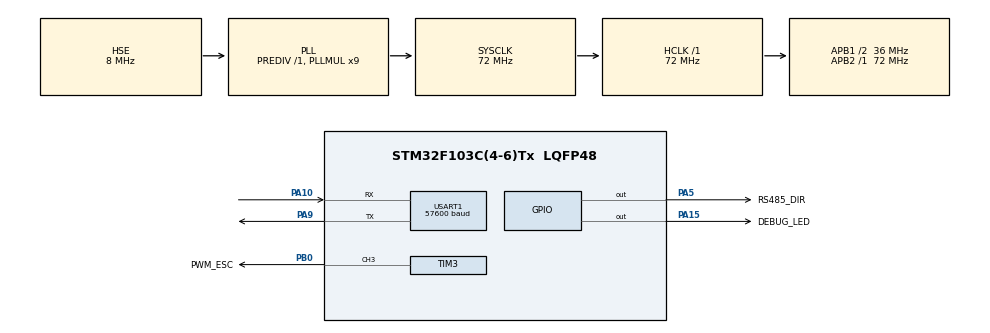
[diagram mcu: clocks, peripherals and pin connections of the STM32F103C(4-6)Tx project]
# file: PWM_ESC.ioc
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Dma.Request0=USART1_TX
Dma.Request1=USART1_RX
Dma.USART1_RX.1.Direction=DMA_PERIPH_TO_MEMORY
Dma.USART1_RX.1.Instance=DMA1_Channel5
Dma.USART1_RX.1.MemDataAlignment=DMA_MDATAALIGN_BYTE
Dma.USART1_RX.1.MemInc=DMA_MINC_ENABLE
Dma.USART1_RX.1.Mode=DMA_NORMAL
Dma.USART1_RX.1.PeriphDataAlignment=DMA_PDATAALIGN_BYTE
Dma.USART1_RX.1.PeriphInc=DMA_PINC_DISABLE
Dma.USART1_RX.1.Priority=DMA_PRIORITY_LOW
Dma.USART1_TX.0.Direction=DMA_MEMORY_TO_PERIPH
Dma.USART1_TX.0.Instance=DMA1_Channel4
Dma.USART1_TX.0.MemDataAlignment=DMA_MDATAALIGN_BYTE
Dma.USART1_TX.0.MemInc=DMA_MINC_ENABLE
Dma.USART1_TX.0.Mode=DMA_NORMAL
Dma.USART1_TX.0.PeriphDataAlignment=DMA_PDATAALIGN_BYTE
Dma.USART1_TX.0.PeriphInc=DMA_PINC_DISABLE
Dma.USART1_TX.0.Priority=DMA_PRIORITY_LOW
Mcu.Family=STM32F1
Mcu.Name=STM32F103C(4-6)Tx
Mcu.Package=LQFP48
NVIC.DMA1_Channel4_IRQn=true\:0\:0\:false\:false\:true\:false\:true
NVIC.DMA1_Channel5_IRQn=true\:0\:0\:false\:false\:true\:false\:true
NVIC.FLASH_IRQn=true\:0\:0\:false\:false\:true\:true\:true
NVIC.PriorityGroup=NVIC_PRIORITYGROUP_4
NVIC.RCC_IRQn=true\:0\:0\:false\:false\:true\:true\:false
NVIC.USART1_IRQn=true\:0\:0\:false\:false\:true\:true\:true
PA10.GPIO_PuPd=GPIO_PULLUP
PA10.Mode=Asynchronous
PA10.Signal=USART1_RX
PA13.Mode=Serial_Wire
PA13.Signal=SYS_JTMS-SWDIO
PA14.Mode=Serial_Wire
PA14.Signal=SYS_JTCK-SWCLK
PA15.GPIO_Label=DEBUG_LED
PA15.Signal=GPIO_Output
PA5.GPIO_Label=RS485_DIR
PA5.GPIO_Speed=GPIO_SPEED_FREQ_HIGH
PA5.Signal=GPIO_Output
PA9.Mode=Asynchronous
PA9.Signal=USART1_TX
PB0.GPIO_Label=PWM_ESC
PB0.Signal=S_TIM3_CH3
PD0-OSC_IN.Mode=HSE-External-Oscillator
PD0-OSC_IN.Signal=RCC_OSC_IN
PD1-OSC_OUT.Mode=HSE-External-Oscillator
PD1-OSC_OUT.Signal=RCC_OSC_OUT
ProjectManager.HeapSize=0x400
ProjectManager.StackSize=0x400
ProjectManager.TargetToolchain=TrueSTUDIO
RCC.AHBFreq_Value=72000000
RCC.APB1CLKDivider=RCC_HCLK_DIV2
RCC.APB1Freq_Value=36000000
RCC.APB1TimFreq_Value=72000000
RCC.APB2Freq_Value=72000000
RCC.APB2TimFreq_Value=72000000
RCC.HCLKFreq_Value=72000000
RCC.PLLMUL=RCC_PLL_MUL9
RCC.PLLSourceVirtual=RCC_PLLSOURCE_HSE
RCC.SYSCLKFreq_VALUE=72000000
RCC.SYSCLKSource=RCC_SYSCLKSOURCE_PLLCLK
RCC.USBFreq_Value=72000000
SH.S_TIM3_CH3.0=TIM3_CH3,PWM Generation3 CH3
TIM3.Channel-PWM\ Generation3\ CH3=TIM_CHANNEL_3
TIM3.Period=19999
TIM3.Prescaler=71
USART1.BaudRate=57600
USART1.VirtualMode=VM_ASYNC
board=custom

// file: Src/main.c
/* USER CODE BEGIN Header */
/**
  ******************************************************************************
  * @file           : main.c
  * @brief          : Main program body
  ******************************************************************************
  * @attention
  *
  * <h2><center>&copy; Copyright (c) 2020 STMicroelectronics.
  * All rights reserved.</center></h2>
  *
  * This software component is licensed by ST under BSD 3-Clause license,
  * the "License"; You may not use this file except in compliance with the
  * License. You may obtain a copy of the License at:
  *                        opensource.org/licenses/BSD-3-Clause
  *
  ******************************************************************************
  */
/* USER CODE END Header */

#include "main.h"

TIM_HandleTypeDef htim3;

UART_HandleTypeDef huart1;
DMA_HandleTypeDef hdma_usart1_tx;
DMA_HandleTypeDef hdma_usart1_rx;

/* USER CODE BEGIN PV */

extern esc_settings esc_struct;
uint8_t rx_flag = 0;
uint8_t rx_array[RECEIVE_BUFFER_SIZE] = {0};

/* USER CODE END PV */

void SystemClock_Config(void);
static void MX_GPIO_Init(void);
static void MX_DMA_Init(void);
static void MX_TIM3_Init(void);
static void MX_USART1_UART_Init(void);

int main(void)
{

  /* MCU Configuration--------------------------------------------------------*/

  /* Reset of all peripherals, Initializes the Flash interface and the Systick. */

	HAL_Init();

  /* Configure the system clock */
  SystemClock_Config();

  /* Initialize all configured peripherals */
  MX_GPIO_Init();
  MX_DMA_Init();
  MX_TIM3_Init();
  MX_USART1_UART_Init();

  /* Infinite loop */
  /* USER CODE BEGIN WHILE */

  FLASH_ReadSettings(&esc_struct);

  HAL_GPIO_WritePin(RS485_DIR_GPIO_Port, RS485_DIR_Pin, RESET);
  HAL_GPIO_WritePin(DEBUG_LED_GPIO_Port, DEBUG_LED_Pin, RESET);

  HAL_TIM_PWM_Start(&htim3, TIM_CHANNEL_3);
  esc_struct.PWM_duty = 0;
  update_esc_settings(&esc_struct);
  HAL_Delay(3000);

  HAL_UART_Receive_IT(&huart1, rx_array, 1);

  while (1)
  {
    /* USER CODE END WHILE */

  }
}

void SystemClock_Config(void)
{
  RCC_OscInitTypeDef RCC_OscInitStruct = {0};
  RCC_ClkInitTypeDef RCC_ClkInitStruct = {0};

  /** Initializes the CPU, AHB and APB busses clocks
  */
  RCC_OscInitStruct.OscillatorType = RCC_OSCILLATORTYPE_HSE;
  RCC_OscInitStruct.HSEState = RCC_HSE_ON;
  RCC_OscInitStruct.HSEPredivValue = RCC_HSE_PREDIV_DIV1;
  RCC_OscInitStruct.HSIState = RCC_HSI_ON;
  RCC_OscInitStruct.PLL.PLLState = RCC_PLL_ON;
  RCC_OscInitStruct.PLL.PLLSource = RCC_PLLSOURCE_HSE;
  RCC_OscInitStruct.PLL.PLLMUL = RCC_PLL_MUL9;
  if (HAL_RCC_OscConfig(&RCC_OscInitStruct) != HAL_OK)
  {
    Error_Handler();
  }
  /** Initializes the CPU, AHB and APB busses clocks
  */
  RCC_ClkInitStruct.ClockType = RCC_CLOCKTYPE_HCLK|RCC_CLOCKTYPE_SYSCLK
                              |RCC_CLOCKTYPE_PCLK1|RCC_CLOCKTYPE_PCLK2;
  RCC_ClkInitStruct.SYSCLKSource = RCC_SYSCLKSOURCE_PLLCLK;
  RCC_ClkInitStruct.AHBCLKDivider = RCC_SYSCLK_DIV1;
  RCC_ClkInitStruct.APB1CLKDivider = RCC_HCLK_DIV2;
  RCC_ClkInitStruct.APB2CLKDivider = RCC_HCLK_DIV1;

  if (HAL_RCC_ClockConfig(&RCC_ClkInitStruct, FLASH_LATENCY_2) != HAL_OK)
  {
    Error_Handler();
  }
}

static void MX_TIM3_Init(void)
{

  TIM_MasterConfigTypeDef sMasterConfig = {0};
  TIM_OC_InitTypeDef sConfigOC = {0};

  htim3.Instance = TIM3;
  htim3.Init.Prescaler = 71;
  htim3.Init.CounterMode = TIM_COUNTERMODE_UP;
  htim3.Init.Period = 19999;
  htim3.Init.ClockDivision = TIM_CLOCKDIVISION_DIV1;
  htim3.Init.AutoReloadPreload = TIM_AUTORELOAD_PRELOAD_DISABLE;
  if (HAL_TIM_PWM_Init(&htim3) != HAL_OK)
  {
    Error_Handler();
  }
  sMasterConfig.MasterOutputTrigger = TIM_TRGO_RESET;
  sMasterConfig.MasterSlaveMode = TIM_MASTERSLAVEMODE_DISABLE;
  if (HAL_TIMEx_MasterConfigSynchronization(&htim3, &sMasterConfig) != HAL_OK)
  {
    Error_Handler();
  }
  sConfigOC.OCMode = TIM_OCMODE_PWM1;
  sConfigOC.Pulse = 0;
  sConfigOC.OCPolarity = TIM_OCPOLARITY_HIGH;
  sConfigOC.OCFastMode = TIM_OCFAST_DISABLE;
  if (HAL_TIM_PWM_ConfigChannel(&htim3, &sConfigOC, TIM_CHANNEL_3) != HAL_OK)
  {
    Error_Handler();
  }
  HAL_TIM_MspPostInit(&htim3);

}

static void MX_USART1_UART_Init(void)
{

  huart1.Instance = USART1;
  huart1.Init.BaudRate = 57600;
  huart1.Init.WordLength = UART_WORDLENGTH_8B;
  huart1.Init.StopBits = UART_STOPBITS_1;
  huart1.Init.Parity = UART_PARITY_NONE;
  huart1.Init.Mode = UART_MODE_TX_RX;
  huart1.Init.HwFlowCtl = UART_HWCONTROL_NONE;
  huart1.Init.OverSampling = UART_OVERSAMPLING_16;
  if (HAL_UART_Init(&huart1) != HAL_OK)
  {
    Error_Handler();
  }

}

static void MX_DMA_Init(void)
{

  /* DMA controller clock enable */
  __HAL_RCC_DMA1_CLK_ENABLE();

  /* DMA interrupt init */
  /* DMA1_Channel4_IRQn interrupt configuration */
  HAL_NVIC_SetPriority(DMA1_Channel4_IRQn, 0, 0);
  HAL_NVIC_EnableIRQ(DMA1_Channel4_IRQn);
  /* DMA1_Channel5_IRQn interrupt configuration */
  HAL_NVIC_SetPriority(DMA1_Channel5_IRQn, 0, 0);
  HAL_NVIC_EnableIRQ(DMA1_Channel5_IRQn);

}

static void MX_GPIO_Init(void)
{
  GPIO_InitTypeDef GPIO_InitStruct = {0};

  /* GPIO Ports Clock Enable */
  __HAL_RCC_GPIOD_CLK_ENABLE();
  __HAL_RCC_GPIOA_CLK_ENABLE();
  __HAL_RCC_GPIOB_CLK_ENABLE();

  /*Configure GPIO pin Output Level */
  HAL_GPIO_WritePin(GPIOA, RS485_DIR_Pin|DEBUG_LED_Pin, GPIO_PIN_RESET);

  /*Configure GPIO pin : RS485_DIR_Pin */
  GPIO_InitStruct.Pin = RS485_DIR_Pin;
  GPIO_InitStruct.Mode = GPIO_MODE_OUTPUT_PP;
  GPIO_InitStruct.Pull = GPIO_NOPULL;
  GPIO_InitStruct.Speed = GPIO_SPEED_FREQ_HIGH;
  HAL_GPIO_Init(RS485_DIR_GPIO_Port, &GPIO_InitStruct);

  /*Configure GPIO pin : DEBUG_LED_Pin */
  GPIO_InitStruct.Pin = DEBUG_LED_Pin;
  GPIO_InitStruct.Mode = GPIO_MODE_OUTPUT_PP;
  GPIO_InitStruct.Pull = GPIO_NOPULL;
  GPIO_InitStruct.Speed = GPIO_SPEED_FREQ_LOW;
  HAL_GPIO_Init(DEBUG_LED_GPIO_Port, &GPIO_InitStruct);

}

void Error_Handler(void)
{
}

/************************ (C) COPYRIGHT STMicroelectronics *****END OF FILE****/
